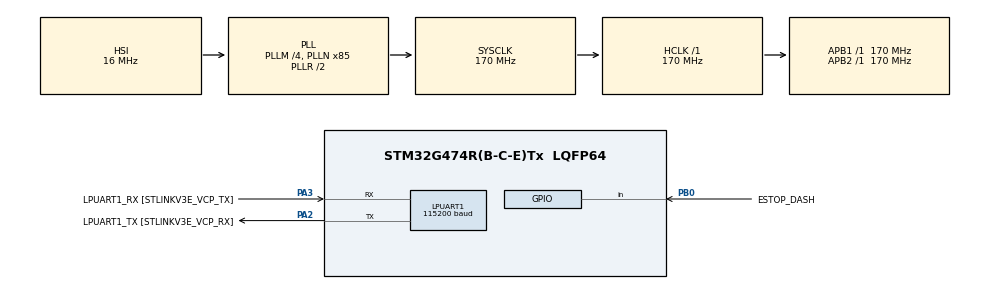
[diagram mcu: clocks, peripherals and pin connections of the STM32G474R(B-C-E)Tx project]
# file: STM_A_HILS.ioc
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FREERTOS.Tasks01=defaultTask,24,128,StartDefaultTask,Default,NULL,Dynamic,NULL,NULL;uROS,24,3000,StartuROS,Default,NULL,Dynamic,NULL,NULL
FREERTOS.configTOTAL_HEAP_SIZE=51200
LPUART1.BaudRate=115200
Mcu.Family=STM32G4
Mcu.Name=STM32G474R(B-C-E)Tx
Mcu.Package=LQFP64
NVIC.LPUART1_IRQn=true\:5\:0\:false\:false\:true\:true\:true\:true\:true
NVIC.PriorityGroup=NVIC_PRIORITYGROUP_4
PA13.GPIO_Label=T_SWDIO
PA13.Signal=SYS_JTMS-SWDIO
PA14.GPIO_Label=T_SWCLK
PA14.Signal=SYS_JTCK-SWCLK
PA2.GPIO_Label=LPUART1_TX [STLINKV3E_VCP_RX]
PA2.Mode=Asynchronous
PA2.Signal=LPUART1_TX
PA3.GPIO_Label=LPUART1_RX [STLINKV3E_VCP_TX]
PA3.Mode=Asynchronous
PA3.Signal=LPUART1_RX
PB0.GPIO_Label=ESTOP_DASH
PB0.GPIO_PuPd=GPIO_PULLUP
PB0.Signal=GPIO_Input
PB3.GPIO_Label=T_SWO
PB3.Signal=SYS_JTDO-SWO
PC14-OSC32_IN.GPIO_Label=RCC_OSC32_IN
PC14-OSC32_IN.Signal=RCC_OSC32_IN
PC15-OSC32_OUT.GPIO_Label=RCC_OSC32_OUT
PC15-OSC32_OUT.Signal=RCC_OSC32_OUT
PF0-OSC_IN.GPIO_Label=RCC_OSC_IN
PF0-OSC_IN.Signal=RCC_OSC_IN
PF1-OSC_OUT.GPIO_Label=RCC_OSC_OUT
PF1-OSC_OUT.Signal=RCC_OSC_OUT
ProjectManager.HeapSize=0x200
ProjectManager.StackSize=0x400
ProjectManager.TargetToolchain=STM32CubeIDE
RCC.ADC12Freq_Value=170000000
RCC.ADC345Freq_Value=170000000
RCC.AHBFreq_Value=170000000
RCC.APB1Freq_Value=170000000
RCC.APB1TimFreq_Value=170000000
RCC.APB2Freq_Value=170000000
RCC.APB2TimFreq_Value=170000000
RCC.CortexFreq_Value=170000000
RCC.EXTERNAL_CLOCK_VALUE=12288000
RCC.HCLKFreq_Value=170000000
RCC.HSE_VALUE=24000000
RCC.HSI48_VALUE=48000000
RCC.HSI_VALUE=16000000
RCC.LSE_VALUE=32768
RCC.PLLM=RCC_PLLM_DIV4
RCC.PLLN=85
RCC.RTCClockSelection=RCC_RTCCLKSOURCE_LSE
RCC.SYSCLKFreq_VALUE=170000000
RCC.SYSCLKSource=RCC_SYSCLKSOURCE_PLLCLK
RCC.USBFreq_Value=170000000
RCC.VCOOutputFreq_Value=340000000
VP_FREERTOS_VS_CMSIS_V2.Mode=CMSIS_V2
VP_SYS_VS_DBSignals.Mode=DisableDeadBatterySignals
board=NUCLEO-G474RE

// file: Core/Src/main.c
/* USER CODE BEGIN Header */
/**
  ******************************************************************************
  * @file           : main.c
  * @brief          : Main program body
  ******************************************************************************
  * @attention
  *
  * Copyright (c) 2026 STMicroelectronics.
  * All rights reserved.
  *
  * This software is licensed under terms that can be found in the LICENSE file
  * in the root directory of this software component.
  * If no LICENSE file comes with this software, it is provided AS-IS.
  *
  ******************************************************************************
  */
/* USER CODE END Header */
#include "main.h"
#include "cmsis_os.h"

/* USER CODE BEGIN Includes */
#include <rcl/rcl.h>
#include <rcl/error_handling.h>
#include <rclc/rclc.h>
#include <rclc/executor.h>
#include <uxr/client/transport.h>
#include <rmw_microxrcedds_c/config.h>
#include <rmw_microros/rmw_microros.h>
#include <std_msgs/msg/u_int8.h>
/* USER CODE END Includes */

UART_HandleTypeDef hlpuart1;

/* Definitions for defaultTask */
osThreadId_t defaultTaskHandle;
const osThreadAttr_t defaultTask_attributes = {
  .name = "defaultTask",
  .priority = (osPriority_t) osPriorityNormal,
  .stack_size = 128 * 4
};
/* Definitions for uROS */
osThreadId_t uROSHandle;
const osThreadAttr_t uROS_attributes = {
  .name = "uROS",
  .priority = (osPriority_t) osPriorityNormal,
  .stack_size = 3000 * 4
};

void SystemClock_Config(void);
static void MX_GPIO_Init(void);
static void MX_LPUART1_UART_Init(void);
void StartDefaultTask(void *argument);
void StartuROS(void *argument);

int main(void)
{

  /* MCU Configuration--------------------------------------------------------*/

  /* Reset of all peripherals, Initializes the Flash interface and the Systick. */
  HAL_Init();

  /* Configure the system clock */
  SystemClock_Config();

  /* Initialize all configured peripherals */
  MX_GPIO_Init();
  MX_LPUART1_UART_Init();

  /* Init scheduler */
  osKernelInitialize();

  /* Create the thread(s) */
  /* creation of defaultTask */
  defaultTaskHandle = osThreadNew(StartDefaultTask, NULL, &defaultTask_attributes);

  /* creation of uROS */
  uROSHandle = osThreadNew(StartuROS, NULL, &uROS_attributes);

  /* Start scheduler */
  osKernelStart();

  /* We should never get here as control is now taken by the scheduler */

  /* Infinite loop */
  while (1)
  {

  }
}

void SystemClock_Config(void)
{
  RCC_OscInitTypeDef RCC_OscInitStruct = {0};
  RCC_ClkInitTypeDef RCC_ClkInitStruct = {0};

  /** Configure the main internal regulator output voltage
  */
  HAL_PWREx_ControlVoltageScaling(PWR_REGULATOR_VOLTAGE_SCALE1_BOOST);

  /** Initializes the RCC Oscillators according to the specified parameters
  * in the RCC_OscInitTypeDef structure.
  */
  RCC_OscInitStruct.OscillatorType = RCC_OSCILLATORTYPE_HSI;
  RCC_OscInitStruct.HSIState = RCC_HSI_ON;
  RCC_OscInitStruct.HSICalibrationValue = RCC_HSICALIBRATION_DEFAULT;
  RCC_OscInitStruct.PLL.PLLState = RCC_PLL_ON;
  RCC_OscInitStruct.PLL.PLLSource = RCC_PLLSOURCE_HSI;
  RCC_OscInitStruct.PLL.PLLM = RCC_PLLM_DIV4;
  RCC_OscInitStruct.PLL.PLLN = 85;
  RCC_OscInitStruct.PLL.PLLP = RCC_PLLP_DIV2;
  RCC_OscInitStruct.PLL.PLLQ = RCC_PLLQ_DIV2;
  RCC_OscInitStruct.PLL.PLLR = RCC_PLLR_DIV2;
  if (HAL_RCC_OscConfig(&RCC_OscInitStruct) != HAL_OK)
  {
    Error_Handler();
  }

  /** Initializes the CPU, AHB and APB buses clocks
  */
  RCC_ClkInitStruct.ClockType = RCC_CLOCKTYPE_HCLK|RCC_CLOCKTYPE_SYSCLK
                              |RCC_CLOCKTYPE_PCLK1|RCC_CLOCKTYPE_PCLK2;
  RCC_ClkInitStruct.SYSCLKSource = RCC_SYSCLKSOURCE_PLLCLK;
  RCC_ClkInitStruct.AHBCLKDivider = RCC_SYSCLK_DIV1;
  RCC_ClkInitStruct.APB1CLKDivider = RCC_HCLK_DIV1;
  RCC_ClkInitStruct.APB2CLKDivider = RCC_HCLK_DIV1;

  if (HAL_RCC_ClockConfig(&RCC_ClkInitStruct, FLASH_LATENCY_4) != HAL_OK)
  {
    Error_Handler();
  }
}

static void MX_LPUART1_UART_Init(void)
{

  hlpuart1.Instance = LPUART1;
  hlpuart1.Init.BaudRate = 115200;
  hlpuart1.Init.WordLength = UART_WORDLENGTH_8B;
  hlpuart1.Init.StopBits = UART_STOPBITS_1;
  hlpuart1.Init.Parity = UART_PARITY_NONE;
  hlpuart1.Init.Mode = UART_MODE_TX_RX;
  hlpuart1.Init.HwFlowCtl = UART_HWCONTROL_NONE;
  hlpuart1.Init.OneBitSampling = UART_ONE_BIT_SAMPLE_DISABLE;
  hlpuart1.Init.ClockPrescaler = UART_PRESCALER_DIV1;
  hlpuart1.AdvancedInit.AdvFeatureInit = UART_ADVFEATURE_NO_INIT;
  if (HAL_UART_Init(&hlpuart1) != HAL_OK)
  {
    Error_Handler();
  }
  if (HAL_UARTEx_SetTxFifoThreshold(&hlpuart1, UART_TXFIFO_THRESHOLD_1_8) != HAL_OK)
  {
    Error_Handler();
  }
  if (HAL_UARTEx_SetRxFifoThreshold(&hlpuart1, UART_RXFIFO_THRESHOLD_1_8) != HAL_OK)
  {
    Error_Handler();
  }
  if (HAL_UARTEx_DisableFifoMode(&hlpuart1) != HAL_OK)
  {
    Error_Handler();
  }

}

static void MX_GPIO_Init(void)
{
  GPIO_InitTypeDef GPIO_InitStruct = {0};

  /* GPIO Ports Clock Enable */
  __HAL_RCC_GPIOC_CLK_ENABLE();
  __HAL_RCC_GPIOF_CLK_ENABLE();
  __HAL_RCC_GPIOA_CLK_ENABLE();
  __HAL_RCC_GPIOB_CLK_ENABLE();

  /*Configure GPIO pin : ESTOP_DASH_Pin */
  GPIO_InitStruct.Pin = ESTOP_DASH_Pin;
  GPIO_InitStruct.Mode = GPIO_MODE_INPUT;
  GPIO_InitStruct.Pull = GPIO_PULLUP;
  HAL_GPIO_Init(ESTOP_DASH_GPIO_Port, &GPIO_InitStruct);

}

/* USER CODE BEGIN 4 */
bool cubemx_transport_open(struct uxrCustomTransport * transport);
bool cubemx_transport_close(struct uxrCustomTransport * transport);
size_t cubemx_transport_write(struct uxrCustomTransport* transport, const uint8_t * buf, size_t len, uint8_t * err);
size_t cubemx_transport_read(struct uxrCustomTransport* transport, uint8_t* buf, size_t len, int timeout, uint8_t* err);

void * microros_allocate(size_t size, void * state);
void microros_deallocate(void * pointer, void * state);
void * microros_reallocate(void * pointer, size_t size, void * state);
void * microros_zero_allocate(size_t number_of_elements, size_t size_of_element, void * state);
/* USER CODE END 4 */

void StartDefaultTask(void *argument)
{
  for(;;)
  {
    osDelay(1);
  }
}

void StartuROS(void *argument)
{
  /* USER CODE BEGIN StartuROS */
  // micro-ROS transport 설정
  rmw_uros_set_custom_transport(
      true,
      (void *) &hlpuart1,
      cubemx_transport_open,
      cubemx_transport_close,
      cubemx_transport_write,
      cubemx_transport_read);

  // FreeRTOS allocator 설정
  rcl_allocator_t freeRTOS_allocator = rcutils_get_zero_initialized_allocator();
  freeRTOS_allocator.allocate = microros_allocate;
  freeRTOS_allocator.deallocate = microros_deallocate;
  freeRTOS_allocator.reallocate = microros_reallocate;
  freeRTOS_allocator.zero_allocate = microros_zero_allocate;

  if (!rcutils_set_default_allocator(&freeRTOS_allocator)) {
      printf("Error on default allocators (line %d)\n", __LINE__);
  }

  // micro-ROS 앱
  rcl_publisher_t publisher;
  std_msgs__msg__UInt8 msg;
  rclc_support_t support;
  rcl_allocator_t allocator;
  rcl_node_t node;

  allocator = rcl_get_default_allocator();

  rclc_support_init(&support, 0, NULL, &allocator);
  rclc_node_init_default(&node, "stm_a_hils_node", "", &support);

  rclc_publisher_init_default(
      &publisher,
      &node,
      ROSIDL_GET_MSG_TYPE_SUPPORT(std_msgs, msg, UInt8),
      "/estop/status");

  msg.data = 0;

  for(;;)
  {
      // PB0 읽기 (PULLUP이라 눌리면 LOW → RESET) ESTOP_DASH_GPIO_Port = GPIOB ESTOP_DASH_Pin = PB0
      GPIO_PinState pin = HAL_GPIO_ReadPin(ESTOP_DASH_GPIO_Port, ESTOP_DASH_Pin);
      msg.data = (pin == GPIO_PIN_RESET) ? 1 : 0;

      rcl_publish(&publisher, &msg, NULL);
      osDelay(50);  // 20Hz
  }

  /* USER CODE END StartuROS */
}

void Error_Handler(void)
{
  __disable_irq();
  while (1)
  {
  }
}
